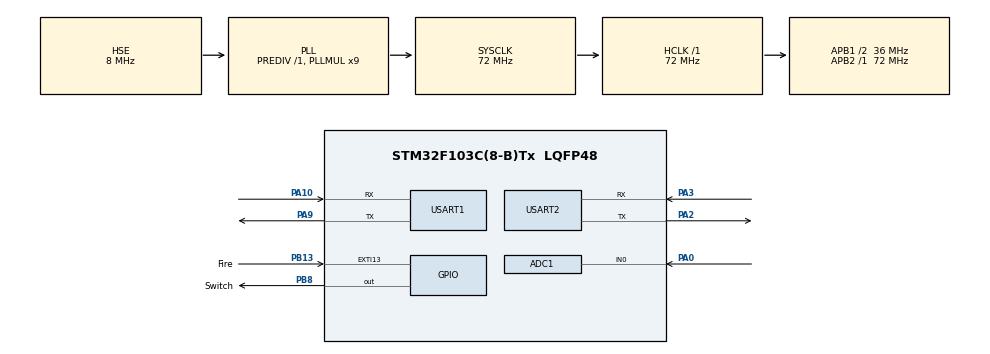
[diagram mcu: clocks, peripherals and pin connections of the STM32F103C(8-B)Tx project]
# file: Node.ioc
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ADC1.Channel-0\#ChannelRegularConversion=ADC_CHANNEL_0
ADC1.ContinuousConvMode=ENABLE
ADC1.NbrOfConversionFlag=1
ADC1.Rank-0\#ChannelRegularConversion=1
ADC1.SamplingTime-0\#ChannelRegularConversion=ADC_SAMPLETIME_239CYCLES_5
ADC1.master=1
Dma.ADC1.0.Direction=DMA_PERIPH_TO_MEMORY
Dma.ADC1.0.Instance=DMA1_Channel1
Dma.ADC1.0.MemDataAlignment=DMA_MDATAALIGN_WORD
Dma.ADC1.0.MemInc=DMA_MINC_ENABLE
Dma.ADC1.0.Mode=DMA_NORMAL
Dma.ADC1.0.PeriphDataAlignment=DMA_PDATAALIGN_WORD
Dma.ADC1.0.PeriphInc=DMA_PINC_DISABLE
Dma.ADC1.0.Priority=DMA_PRIORITY_LOW
Dma.Request0=ADC1
Dma.Request1=USART2_RX
Dma.Request2=USART2_TX
Dma.Request3=USART1_RX
Dma.Request4=USART1_TX
Dma.USART1_RX.3.Direction=DMA_PERIPH_TO_MEMORY
Dma.USART1_RX.3.Instance=DMA1_Channel5
Dma.USART1_RX.3.MemDataAlignment=DMA_MDATAALIGN_BYTE
Dma.USART1_RX.3.MemInc=DMA_MINC_ENABLE
Dma.USART1_RX.3.Mode=DMA_NORMAL
Dma.USART1_RX.3.PeriphDataAlignment=DMA_PDATAALIGN_BYTE
Dma.USART1_RX.3.PeriphInc=DMA_PINC_DISABLE
Dma.USART1_RX.3.Priority=DMA_PRIORITY_LOW
Dma.USART1_TX.4.Direction=DMA_MEMORY_TO_PERIPH
Dma.USART1_TX.4.Instance=DMA1_Channel4
Dma.USART1_TX.4.MemDataAlignment=DMA_MDATAALIGN_BYTE
Dma.USART1_TX.4.MemInc=DMA_MINC_ENABLE
Dma.USART1_TX.4.Mode=DMA_NORMAL
Dma.USART1_TX.4.PeriphDataAlignment=DMA_PDATAALIGN_BYTE
Dma.USART1_TX.4.PeriphInc=DMA_PINC_DISABLE
Dma.USART1_TX.4.Priority=DMA_PRIORITY_LOW
Dma.USART2_RX.1.Direction=DMA_PERIPH_TO_MEMORY
Dma.USART2_RX.1.Instance=DMA1_Channel6
Dma.USART2_RX.1.MemDataAlignment=DMA_MDATAALIGN_BYTE
Dma.USART2_RX.1.MemInc=DMA_MINC_ENABLE
Dma.USART2_RX.1.Mode=DMA_NORMAL
Dma.USART2_RX.1.PeriphDataAlignment=DMA_PDATAALIGN_BYTE
Dma.USART2_RX.1.PeriphInc=DMA_PINC_DISABLE
Dma.USART2_RX.1.Priority=DMA_PRIORITY_LOW
Dma.USART2_TX.2.Direction=DMA_MEMORY_TO_PERIPH
Dma.USART2_TX.2.Instance=DMA1_Channel7
Dma.USART2_TX.2.MemDataAlignment=DMA_MDATAALIGN_BYTE
Dma.USART2_TX.2.MemInc=DMA_MINC_ENABLE
Dma.USART2_TX.2.Mode=DMA_NORMAL
Dma.USART2_TX.2.PeriphDataAlignment=DMA_PDATAALIGN_BYTE
Dma.USART2_TX.2.PeriphInc=DMA_PINC_DISABLE
Dma.USART2_TX.2.Priority=DMA_PRIORITY_LOW
Mcu.Family=STM32F1
Mcu.Name=STM32F103C(8-B)Tx
Mcu.Package=LQFP48
NVIC.DMA1_Channel1_IRQn=true\:1\:0\:true\:false\:true\:false\:true\:true
NVIC.DMA1_Channel4_IRQn=true\:1\:0\:true\:false\:true\:false\:true\:true
NVIC.DMA1_Channel5_IRQn=true\:1\:0\:true\:false\:true\:false\:true\:true
NVIC.DMA1_Channel6_IRQn=true\:1\:0\:true\:false\:true\:false\:true\:true
NVIC.DMA1_Channel7_IRQn=true\:1\:0\:true\:false\:true\:false\:true\:true
NVIC.EXTI15_10_IRQn=true\:1\:0\:true\:false\:true\:true\:true\:true
NVIC.PriorityGroup=NVIC_PRIORITYGROUP_4
NVIC.TIM4_IRQn=true\:2\:0\:true\:false\:true\:true\:true\:true
NVIC.USART1_IRQn=true\:2\:0\:true\:false\:true\:false\:true\:true
NVIC.USART2_IRQn=true\:2\:0\:true\:false\:true\:false\:true\:true
PA0-WKUP.Signal=ADCx_IN0
PA10.Mode=Asynchronous
PA10.Signal=USART1_RX
PA13.Mode=Serial_Wire
PA13.Signal=SYS_JTMS-SWDIO
PA14.Mode=Serial_Wire
PA14.Signal=SYS_JTCK-SWCLK
PA2.Mode=Asynchronous
PA2.Signal=USART2_TX
PA3.Mode=Asynchronous
PA3.Signal=USART2_RX
PA9.Mode=Asynchronous
PA9.Signal=USART1_TX
PB13.GPIO_Label=Fire
PB13.GPIO_ModeDefaultEXTI=GPIO_MODE_IT_RISING_FALLING
PB13.Signal=GPXTI13
PB8.GPIO_Label=Switch
PB8.GPIO_PuPd=GPIO_PULLUP
PB8.Signal=GPIO_Output
PC14-OSC32_IN.Mode=LSE-External-Oscillator
PC14-OSC32_IN.Signal=RCC_OSC32_IN
PC15-OSC32_OUT.Mode=LSE-External-Oscillator
PC15-OSC32_OUT.Signal=RCC_OSC32_OUT
PD0-OSC_IN.Mode=HSE-External-Oscillator
PD0-OSC_IN.Signal=RCC_OSC_IN
PD1-OSC_OUT.Mode=HSE-External-Oscillator
PD1-OSC_OUT.Signal=RCC_OSC_OUT
ProjectManager.HeapSize=0x200
ProjectManager.StackSize=0x400
ProjectManager.TargetToolchain=MDK-ARM V5.32
RCC.ADCPresc=RCC_ADCPCLK2_DIV6
RCC.AHBFreq_Value=72000000
RCC.APB1CLKDivider=RCC_HCLK_DIV2
RCC.APB1Freq_Value=36000000
RCC.APB1TimFreq_Value=72000000
RCC.APB2Freq_Value=72000000
RCC.APB2TimFreq_Value=72000000
RCC.HCLKFreq_Value=72000000
RCC.PLLMUL=RCC_PLL_MUL9
RCC.PLLSourceVirtual=RCC_PLLSOURCE_HSE
RCC.SYSCLKFreq_VALUE=72000000
RCC.SYSCLKSource=RCC_SYSCLKSOURCE_PLLCLK
RCC.USBFreq_Value=72000000
SH.ADCx_IN0.0=ADC1_IN0,IN0
TIM4.AutoReloadPreload=TIM_AUTORELOAD_PRELOAD_ENABLE
TIM4.Period=20000-1
TIM4.Prescaler=7200-1
USART1.VirtualMode=VM_ASYNC
USART2.VirtualMode=VM_ASYNC
VP_TIM4_VS_ClockSourceINT.Mode=Internal
board=custom

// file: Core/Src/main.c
/* USER CODE BEGIN Header */
/**
  ******************************************************************************
  * @file           : main.c
  * @brief          : Main program body
  ******************************************************************************
  * @attention
  *
  * Copyright (c) 2024 STMicroelectronics.
  * All rights reserved.
  *
  * This software is licensed under terms that can be found in the LICENSE file
  * in the root directory of this software component.
  * If no LICENSE file comes with this software, it is provided AS-IS.
  *
  ******************************************************************************
  */
/* USER CODE END Header */
#include "main.h"
#include "adc.h"
#include "dma.h"
#include "tim.h"
#include "usart.h"
#include "gpio.h"

/* USER CODE BEGIN PV */
uint8_t Fire_FLAG = 0,Smoke_FLAG = 0;
/* USER CODE END PV */

void SystemClock_Config(void);

int main(void)
{

  /* MCU Configuration--------------------------------------------------------*/

  /* Reset of all peripherals, Initializes the Flash interface and the Systick. */
  HAL_Init();

  /* Configure the system clock */
  SystemClock_Config();

  /* Initialize all configured peripherals */
  MX_GPIO_Init();
  MX_DMA_Init();
  MX_ADC1_Init();
  MX_USART2_UART_Init();
  MX_TIM4_Init();
  MX_USART1_UART_Init();
  /* USER CODE BEGIN 2 */
  HAL_UART_Transmit_DMA(&huart1, "System Start\n", 14);

  HAL_UARTEx_ReceiveToIdle_DMA(&huart1, receiveBuffer, 1024);
  __HAL_DMA_DISABLE_IT(&hdma_usart1_rx, DMA_IT_HT);
  HAL_UART_Transmit_DMA(&huart1, "UART1 Init Over\n", 17);

  sprintf(mqtt_pub_data[1].value, "%d", !HAL_GPIO_ReadPin(Fire_GPIO_Port,Fire_Pin));

  AT_UART_Init();
  HAL_UART_Transmit_DMA(&huart1, "UART_AT Init Over\n", 17);

	AT_MQTT_Init();
	HAL_UART_Transmit_DMA(&huart1, "MQTT Link Over\n", 16);

	HAL_TIM_Base_Start_IT(&htim4);
	HAL_UART_Transmit_DMA(&huart1, "TIM4 Start Over\n", 17);

	HAL_UART_Transmit_DMA(&huart1, "System Init Over\n", 18);
  /* USER CODE END 2 */

  /* Infinite loop */
  while (1)
  {
		if(Fire_FLAG == 1||Smoke_FLAG == 1){
			HAL_Delay(10);
			if(!HAL_GPIO_ReadPin(Switch_GPIO_Port,Switch_Pin))
				HAL_GPIO_WritePin(Switch_GPIO_Port,Switch_Pin,GPIO_PIN_SET);
		}
		else if(Fire_FLAG==0 && Smoke_FLAG == 0){
			HAL_Delay(10);
			if(HAL_GPIO_ReadPin(Switch_GPIO_Port,Switch_Pin))
				HAL_GPIO_WritePin(Switch_GPIO_Port,Switch_Pin,GPIO_PIN_RESET);
		}

  }
}

void SystemClock_Config(void)
{
  RCC_OscInitTypeDef RCC_OscInitStruct = {0};
  RCC_ClkInitTypeDef RCC_ClkInitStruct = {0};
  RCC_PeriphCLKInitTypeDef PeriphClkInit = {0};

  /** Initializes the RCC Oscillators according to the specified parameters
  * in the RCC_OscInitTypeDef structure.
  */
  RCC_OscInitStruct.OscillatorType = RCC_OSCILLATORTYPE_HSE;
  RCC_OscInitStruct.HSEState = RCC_HSE_ON;
  RCC_OscInitStruct.HSEPredivValue = RCC_HSE_PREDIV_DIV1;
  RCC_OscInitStruct.HSIState = RCC_HSI_ON;
  RCC_OscInitStruct.PLL.PLLState = RCC_PLL_ON;
  RCC_OscInitStruct.PLL.PLLSource = RCC_PLLSOURCE_HSE;
  RCC_OscInitStruct.PLL.PLLMUL = RCC_PLL_MUL9;
  if (HAL_RCC_OscConfig(&RCC_OscInitStruct) != HAL_OK)
  {
    Error_Handler();
  }

  /** Initializes the CPU, AHB and APB buses clocks
  */
  RCC_ClkInitStruct.ClockType = RCC_CLOCKTYPE_HCLK|RCC_CLOCKTYPE_SYSCLK
                              |RCC_CLOCKTYPE_PCLK1|RCC_CLOCKTYPE_PCLK2;
  RCC_ClkInitStruct.SYSCLKSource = RCC_SYSCLKSOURCE_PLLCLK;
  RCC_ClkInitStruct.AHBCLKDivider = RCC_SYSCLK_DIV1;
  RCC_ClkInitStruct.APB1CLKDivider = RCC_HCLK_DIV2;
  RCC_ClkInitStruct.APB2CLKDivider = RCC_HCLK_DIV1;

  if (HAL_RCC_ClockConfig(&RCC_ClkInitStruct, FLASH_LATENCY_2) != HAL_OK)
  {
    Error_Handler();
  }
  PeriphClkInit.PeriphClockSelection = RCC_PERIPHCLK_ADC;
  PeriphClkInit.AdcClockSelection = RCC_ADCPCLK2_DIV6;
  if (HAL_RCCEx_PeriphCLKConfig(&PeriphClkInit) != HAL_OK)
  {
    Error_Handler();
  }
}

void Error_Handler(void)
{
  __disable_irq();
  while (1)
  {
  }
}
